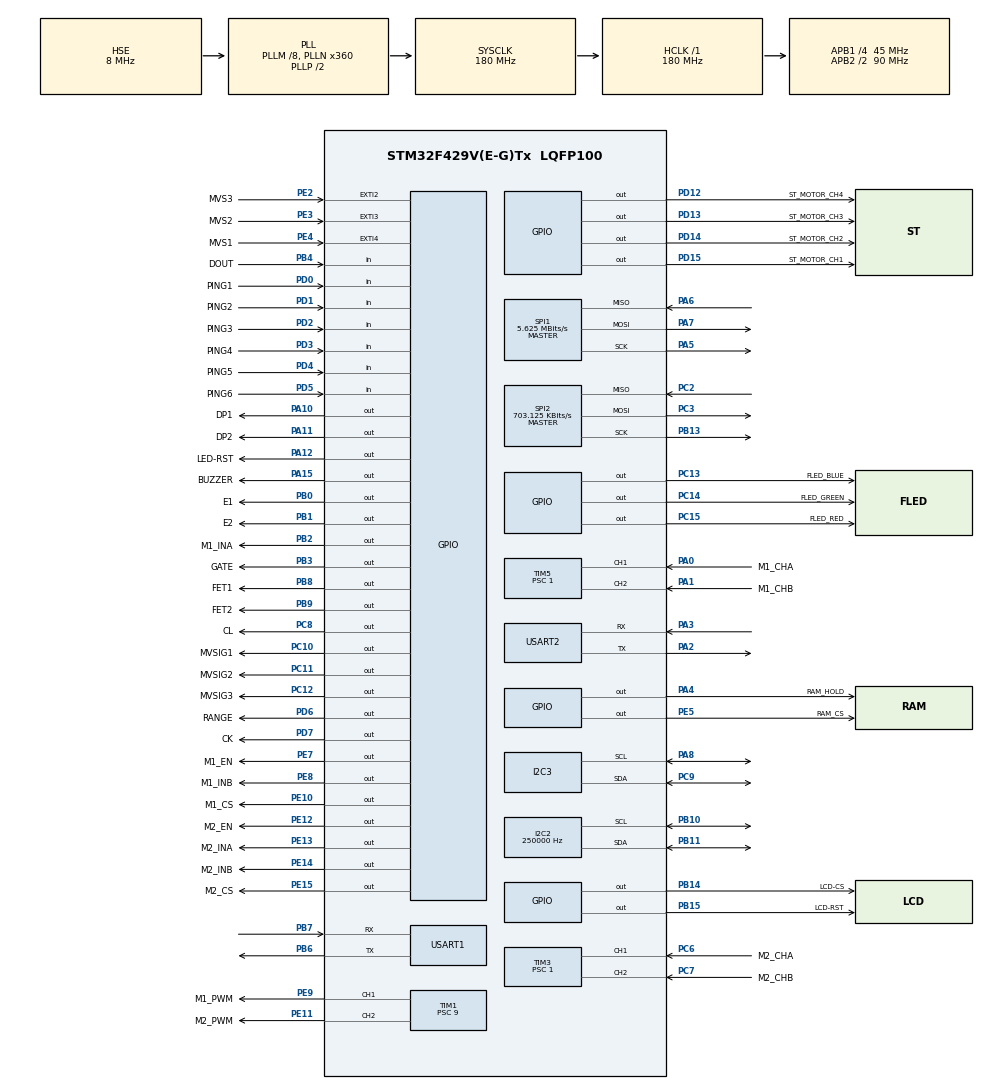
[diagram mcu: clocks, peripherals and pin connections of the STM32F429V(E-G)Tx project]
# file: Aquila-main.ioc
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I2C2.ClockSpeed=250000
I2C2.I2C_Mode=I2C_Fast
I2C3.NoStretchMode=I2C_NOSTRETCH_ENABLE
Mcu.Family=STM32F4
Mcu.Name=STM32F429V(E-G)Tx
Mcu.Package=LQFP100
NVIC.EXTI2_IRQn=true\:1\:0\:true\:false\:true\:true
NVIC.EXTI3_IRQn=true\:1\:0\:true\:false\:true\:true
NVIC.EXTI4_IRQn=true\:1\:0\:true\:false\:true\:true
NVIC.PriorityGroup=NVIC_PRIORITYGROUP_4
NVIC.TIM2_IRQn=true\:0\:0\:true\:false\:true\:true
NVIC.TIM8_TRG_COM_TIM14_IRQn=true\:0\:0\:false\:false\:true\:false
NVIC.TIM8_UP_TIM13_IRQn=true\:3\:0\:true\:false\:true\:true
NVIC.TimeBase=TIM8_TRG_COM_TIM14_IRQn
NVIC.TimeBaseIP=TIM14
PA0/WKUP.GPIO_Label=M1_CHA
PA0/WKUP.Signal=S_TIM5_CH1
PA1.GPIO_Label=M1_CHB
PA1.Signal=S_TIM5_CH2
PA10.GPIO_Label=DP1
PA10.Signal=GPIO_Output
PA11.GPIO_Label=DP2
PA11.Signal=GPIO_Output
PA12.GPIO_Label=LED-RST
PA12.Signal=GPIO_Output
PA13.Mode=Serial_Wire
PA13.Signal=SYS_JTMS-SWDIO
PA14.Mode=Serial_Wire
PA14.Signal=SYS_JTCK-SWCLK
PA15.GPIO_Label=BUZZER
PA15.Signal=GPIO_Output
PA2.Mode=Asynchronous
PA2.Signal=USART2_TX
PA3.Mode=Asynchronous
PA3.Signal=USART2_RX
PA4.GPIO_Label=RAM_HOLD
PA4.Signal=GPIO_Output
PA5.Mode=Full_Duplex_Master
PA5.Signal=SPI1_SCK
PA6.Mode=Full_Duplex_Master
PA6.Signal=SPI1_MISO
PA7.Mode=Full_Duplex_Master
PA7.Signal=SPI1_MOSI
PA8.GPIO_PuPdOD=GPIO_NOPULL
PA8.Mode=I2C
PA8.Signal=I2C3_SCL
PB0.GPIO_Label=E1
PB0.Signal=GPIO_Output
PB1.GPIO_Label=E2
PB1.Signal=GPIO_Output
PB10.Mode=I2C
PB10.Signal=I2C2_SCL
PB11.Mode=I2C
PB11.Signal=I2C2_SDA
PB13.Mode=Full_Duplex_Master
PB13.Signal=SPI2_SCK
PB14.GPIO_Label=LCD-CS
PB14.Signal=GPIO_Output
PB15.GPIO_Label=LCD-RST
PB15.Signal=GPIO_Output
PB2/BOOT1.GPIO_Label=M1_INA
PB2/BOOT1.Signal=GPIO_Output
PB3.GPIO_Label=GATE
PB3.Signal=GPIO_Output
PB4.GPIO_Label=DOUT
PB4.Signal=GPIO_Input
PB6.Mode=Asynchronous
PB6.Signal=USART1_TX
PB7.Mode=Asynchronous
PB7.Signal=USART1_RX
PB8.GPIO_Label=FET1
PB8.Signal=GPIO_Output
PB9.GPIO_Label=FET2
PB9.Signal=GPIO_Output
PC0.GPIO_Label=TOUCH1
PC0.Signal=EVENTOUT
PC1.GPIO_Label=TOUCH2
PC1.Signal=EVENTOUT
PC10.GPIO_Label=MVSIG1
PC10.Signal=GPIO_Output
PC11.GPIO_Label=MVSIG2
PC11.Signal=GPIO_Output
PC12.GPIO_Label=MVSIG3
PC12.Signal=GPIO_Output
PC13.GPIO_Label=FLED_BLUE
PC13.GPIO_PuPd=GPIO_PULLUP
PC13.Signal=GPIO_Output
PC14/OSC32_IN.GPIO_Label=FLED_GREEN
PC14/OSC32_IN.GPIO_ModeDefaultOutputPP=GPIO_MODE_OUTPUT_PP
PC14/OSC32_IN.GPIO_PuPd=GPIO_PULLUP
PC14/OSC32_IN.Signal=GPIO_Output
PC15/OSC32_OUT.GPIO_Label=FLED_RED
PC15/OSC32_OUT.GPIO_PuPd=GPIO_PULLUP
PC15/OSC32_OUT.Signal=GPIO_Output
PC2.Mode=Full_Duplex_Master
PC2.Signal=SPI2_MISO
PC3.Mode=Full_Duplex_Master
PC3.Signal=SPI2_MOSI
PC6.GPIO_Label=M2_CHA
PC6.Signal=S_TIM3_CH1
PC7.GPIO_Label=M2_CHB
PC7.Signal=S_TIM3_CH2
PC8.GPIO_Label=CL
PC8.GPIO_PuPd=GPIO_PULLDOWN
PC8.Signal=GPIO_Output
PC9.GPIO_PuPdOD=GPIO_NOPULL
PC9.Mode=I2C
PC9.Signal=I2C3_SDA
PD0.GPIO_Label=PING1
PD0.Signal=GPIO_Input
PD1.GPIO_Label=PING2
PD1.Signal=GPIO_Input
PD10.GPIO_Label=SW3
PD10.Signal=EVENTOUT
PD12.GPIO_Label=ST_MOTOR_CH4
PD12.PinState=GPIO_PIN_SET
PD12.Signal=GPIO_Output
PD13.GPIO_Label=ST_MOTOR_CH3
PD13.PinState=GPIO_PIN_SET
PD13.Signal=GPIO_Output
PD14.GPIO_Label=ST_MOTOR_CH2
PD14.PinState=GPIO_PIN_SET
PD14.Signal=GPIO_Output
PD15.GPIO_Label=ST_MOTOR_CH1
PD15.PinState=GPIO_PIN_SET
PD15.Signal=GPIO_Output
PD2.GPIO_Label=PING3
PD2.Signal=GPIO_Input
PD3.GPIO_Label=PING4
PD3.Signal=GPIO_Input
PD4.GPIO_Label=PING5
PD4.Signal=GPIO_Input
PD5.GPIO_Label=PING6
PD5.Signal=GPIO_Input
PD6.GPIO_Label=RANGE
PD6.Signal=GPIO_Output
PD7.GPIO_Label=CK
PD7.Signal=GPIO_Output
PD8.GPIO_Label=SW1
PD8.Signal=EVENTOUT
PD9.GPIO_Label=SW2
PD9.Signal=EVENTOUT
PE10.GPIO_Label=M1_CS
PE10.Signal=GPIO_Output
PE11.GPIO_Label=M2_PWM
PE11.Signal=S_TIM1_CH2
PE12.GPIO_Label=M2_EN
PE12.Signal=GPIO_Output
PE13.GPIO_Label=M2_INA
PE13.Signal=GPIO_Output
PE14.GPIO_Label=M2_INB
PE14.Signal=GPIO_Output
PE15.GPIO_Label=M2_CS
PE15.Signal=GPIO_Output
PE2.GPIO_Label=MVS3
PE2.GPIO_ModeDefaultEXTI=GPIO_MODE_IT_FALLING
PE2.Signal=GPXTI2
PE3.GPIO_Label=MVS2
PE3.GPIO_ModeDefaultEXTI=GPIO_MODE_IT_FALLING
PE3.Signal=GPXTI3
PE4.GPIO_Label=MVS1
PE4.GPIO_ModeDefaultEXTI=GPIO_MODE_IT_FALLING
PE4.Signal=GPXTI4
PE5.GPIO_Label=RAM_CS
PE5.Signal=GPIO_Output
PE6.GPIO_Label=ESC
PE6.Signal=S_TIM9_CH2
PE7.GPIO_Label=M1_EN
PE7.Signal=GPIO_Output
PE8.GPIO_Label=M1_INB
PE8.Signal=GPIO_Output
PE9.GPIO_Label=M1_PWM
PE9.Signal=S_TIM1_CH1
PH0/OSC_IN.Mode=HSE-External-Oscillator
PH0/OSC_IN.Signal=RCC_OSC_IN
PH1/OSC_OUT.Mode=HSE-External-Oscillator
PH1/OSC_OUT.Signal=RCC_OSC_OUT
ProjectManager.HeapSize=0x200
ProjectManager.StackSize=0x400
ProjectManager.TargetToolchain=SW4STM32
RCC.48MHZClocksFreq_Value=90000000
RCC.AHBFreq_Value=180000000
RCC.APB1CLKDivider=RCC_HCLK_DIV4
RCC.APB1Freq_Value=45000000
RCC.APB1TimFreq_Value=90000000
RCC.APB2CLKDivider=RCC_HCLK_DIV2
RCC.APB2Freq_Value=90000000
RCC.APB2TimFreq_Value=180000000
RCC.CortexFreq_Value=180000000
RCC.HCLKFreq_Value=180000000
RCC.HSE_VALUE=8000000
RCC.HSI_VALUE=16000000
RCC.LSE_VALUE=32768
RCC.PLLM=8
RCC.PLLN=360
RCC.PLLSourceVirtual=RCC_PLLSOURCE_HSE
RCC.SYSCLKFreq_VALUE=180000000
RCC.SYSCLKSource=RCC_SYSCLKSOURCE_PLLCLK
RCC.VCOOutputFreq_Value=360000000
SH.S_TIM1_CH1.0=TIM1_CH1,PWM Generation1 CH1
SH.S_TIM1_CH2.0=TIM1_CH2,PWM Generation2 CH2
SH.S_TIM3_CH1.0=TIM3_CH1,Encoder_Interface
SH.S_TIM3_CH2.0=TIM3_CH2,Encoder_Interface
SH.S_TIM5_CH1.0=TIM5_CH1,Encoder_Interface
SH.S_TIM5_CH2.0=TIM5_CH2,Encoder_Interface
SH.S_TIM9_CH2.0=TIM9_CH2
SPI1.BaudRatePrescaler=SPI_BAUDRATEPRESCALER_16
SPI1.CalculateBaudRate=5.625 MBits/s
SPI1.Direction=SPI_DIRECTION_2LINES
SPI1.Mode=SPI_MODE_MASTER
SPI1.VirtualType=VM_MASTER
SPI2.BaudRatePrescaler=SPI_BAUDRATEPRESCALER_64
SPI2.CalculateBaudRate=703.125 KBits/s
SPI2.Direction=SPI_DIRECTION_2LINES
SPI2.Mode=SPI_MODE_MASTER
SPI2.VirtualType=VM_MASTER
TIM1.Channel-PWM\ Generation1\ CH1=TIM_CHANNEL_1
TIM1.Channel-PWM\ Generation2\ CH2=TIM_CHANNEL_2
TIM1.Period=1000
TIM1.Prescaler=9
TIM10.Period=65535
TIM10.Prescaler=179
TIM13.Period=500
TIM13.Prescaler=5000
TIM2.Period=63000
TIM2.Prescaler=1
TIM3.Period=65535
TIM3.Prescaler=1
TIM5.Period=65535
TIM5.Prescaler=1
TIM6.Period=10000
TIM6.Prescaler=30
TIM7.Period=65535
TIM7.Prescaler=44
USART1.VirtualMode=VM_ASYNC
USART2.VirtualMode=VM_ASYNC
VP_SYS_VS_tim14.Mode=TIM14
VP_TIM10_VS_ClockSourceINT.Mode=Enable_Timer
VP_TIM13_VS_ClockSourceINT.Mode=Enable_Timer
VP_TIM2_VS_ClockSourceINT.Mode=Internal
VP_TIM6_VS_ClockSourceINT.Mode=Enable_Timer
VP_TIM7_VS_ClockSourceINT.Mode=Enable_Timer
board=custom

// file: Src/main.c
/**
  ******************************************************************************
  * @file           : main.c
  * @brief          : Main program body
  ******************************************************************************
  ** This notice applies to any and all portions of this file
  * that are not between comment pairs USER CODE BEGIN and
  * USER CODE END. Other portions of this file, whether
  * inserted by the user or by software development tools
  * are owned by their respective copyright owners.
  *
  * COPYRIGHT(c) 2019 STMicroelectronics
  *
  * Redistribution and use in source and binary forms, with or without modification,
  * are permitted provided that the following conditions are met:
  *   1. Redistributions of source code must retain the above copyright notice,
  *      this list of conditions and the following disclaimer.
  *   2. Redistributions in binary form must reproduce the above copyright notice,
  *      this list of conditions and the following disclaimer in the documentation
  *      and/or other materials provided with the distribution.
  *   3. Neither the name of STMicroelectronics nor the names of its contributors
  *      may be used to endorse or promote products derived from this software
  *      without specific prior written permission.
  *
  * THIS SOFTWARE IS PROVIDED BY THE COPYRIGHT HOLDERS AND CONTRIBUTORS "AS IS"
  * AND ANY EXPRESS OR IMPLIED WARRANTIES, INCLUDING, BUT NOT LIMITED TO, THE
  * IMPLIED WARRANTIES OF MERCHANTABILITY AND FITNESS FOR A PARTICULAR PURPOSE ARE
  * DISCLAIMED. IN NO EVENT SHALL THE COPYRIGHT HOLDER OR CONTRIBUTORS BE LIABLE
  * FOR ANY DIRECT, INDIRECT, INCIDENTAL, SPECIAL, EXEMPLARY, OR CONSEQUENTIAL
  * DAMAGES (INCLUDING, BUT NOT LIMITED TO, PROCUREMENT OF SUBSTITUTE GOODS OR
  * SERVICES; LOSS OF USE, DATA, OR PROFITS; OR BUSINESS INTERRUPTION) HOWEVER
  * CAUSED AND ON ANY THEORY OF LIABILITY, WHETHER IN CONTRACT, STRICT LIABILITY,
  * OR TORT (INCLUDING NEGLIGENCE OR OTHERWISE) ARISING IN ANY WAY OUT OF THE USE
  * OF THIS SOFTWARE, EVEN IF ADVISED OF THE POSSIBILITY OF SUCH DAMAGE.
  *
  ******************************************************************************
  */
#include "main.h"
#include "stm32f4xx_hal.h"
#include "i2c.h"
#include "spi.h"
#include "tim.h"
#include "usart.h"
#include "gpio.h"

/* USER CODE BEGIN Includes */
#include "wrapper.hpp"
#include "source/interrupt.hpp"
/* USER CODE END Includes */

/* USER CODE BEGIN PV */
/* Private variables ---------------------------------------------------------*/

/* USER CODE END PV */

void SystemClock_Config(void);

/* USER CODE BEGIN PFP */
/* Private function prototypes -----------------------------------------------*/

/* USER CODE END PFP */

int main(void)
{

  /* MCU Configuration----------------------------------------------------------*/

  /* Reset of all peripherals, Initializes the Flash interface and the Systick. */
  HAL_Init();

  /* Configure the system clock */
  SystemClock_Config();

  /* Initialize all configured peripherals */
  MX_GPIO_Init();
  MX_TIM3_Init();
  MX_TIM5_Init();
  MX_SPI1_Init();
  MX_SPI2_Init();
  MX_I2C2_Init();
  MX_TIM1_Init();
  MX_USART1_UART_Init();
  MX_USART2_UART_Init();
  MX_TIM6_Init();
  MX_TIM7_Init();
  MX_TIM13_Init();
  MX_I2C3_Init();
  MX_TIM2_Init();
  MX_TIM10_Init();

  /* Infinite loop */
  /* USER CODE BEGIN WHILE */
  cpploop();
  while (1)
  {

  /* USER CODE END WHILE */

  }

}

void SystemClock_Config(void)
{

  RCC_OscInitTypeDef RCC_OscInitStruct;
  RCC_ClkInitTypeDef RCC_ClkInitStruct;

    /**Configure the main internal regulator output voltage
    */
  __HAL_RCC_PWR_CLK_ENABLE();

  __HAL_PWR_VOLTAGESCALING_CONFIG(PWR_REGULATOR_VOLTAGE_SCALE1);

    /**Initializes the CPU, AHB and APB busses clocks
    */
  RCC_OscInitStruct.OscillatorType = RCC_OSCILLATORTYPE_HSE;
  RCC_OscInitStruct.HSEState = RCC_HSE_ON;
  RCC_OscInitStruct.PLL.PLLState = RCC_PLL_ON;
  RCC_OscInitStruct.PLL.PLLSource = RCC_PLLSOURCE_HSE;
  RCC_OscInitStruct.PLL.PLLM = 8;
  RCC_OscInitStruct.PLL.PLLN = 360;
  RCC_OscInitStruct.PLL.PLLP = RCC_PLLP_DIV2;
  RCC_OscInitStruct.PLL.PLLQ = 4;
  if (HAL_RCC_OscConfig(&RCC_OscInitStruct) != HAL_OK)
  {
    _Error_Handler(__FILE__, __LINE__);
  }

    /**Activate the Over-Drive mode
    */
  if (HAL_PWREx_EnableOverDrive() != HAL_OK)
  {
    _Error_Handler(__FILE__, __LINE__);
  }

    /**Initializes the CPU, AHB and APB busses clocks
    */
  RCC_ClkInitStruct.ClockType = RCC_CLOCKTYPE_HCLK|RCC_CLOCKTYPE_SYSCLK
                              |RCC_CLOCKTYPE_PCLK1|RCC_CLOCKTYPE_PCLK2;
  RCC_ClkInitStruct.SYSCLKSource = RCC_SYSCLKSOURCE_PLLCLK;
  RCC_ClkInitStruct.AHBCLKDivider = RCC_SYSCLK_DIV1;
  RCC_ClkInitStruct.APB1CLKDivider = RCC_HCLK_DIV4;
  RCC_ClkInitStruct.APB2CLKDivider = RCC_HCLK_DIV2;

  if (HAL_RCC_ClockConfig(&RCC_ClkInitStruct, FLASH_LATENCY_5) != HAL_OK)
  {
    _Error_Handler(__FILE__, __LINE__);
  }

    /**Configure the Systick interrupt time
    */
  HAL_SYSTICK_Config(HAL_RCC_GetHCLKFreq()/1000);

    /**Configure the Systick
    */
  HAL_SYSTICK_CLKSourceConfig(SYSTICK_CLKSOURCE_HCLK);

  /* SysTick_IRQn interrupt configuration */
  HAL_NVIC_SetPriority(SysTick_IRQn, 0, 0);
}

/* USER CODE BEGIN 4 */
void HAL_GPIO_EXTI_Callback(uint16_t GPIO_Pin){
	GPIO_interrupt_callback(GPIO_Pin);
	return;
}

/* USER CODE END 4 */

void HAL_TIM_PeriodElapsedCallback(TIM_HandleTypeDef *htim)
{
  /* USER CODE BEGIN Callback 0 */

  interrupt_callback(htim);
  /* USER CODE END Callback 0 */
  if (htim->Instance == TIM14) {
    HAL_IncTick();
  }
}

void _Error_Handler(char *file, int line)
{
  while(1)
  {
  }
}

/************************ (C) COPYRIGHT STMicroelectronics *****END OF FILE****/
